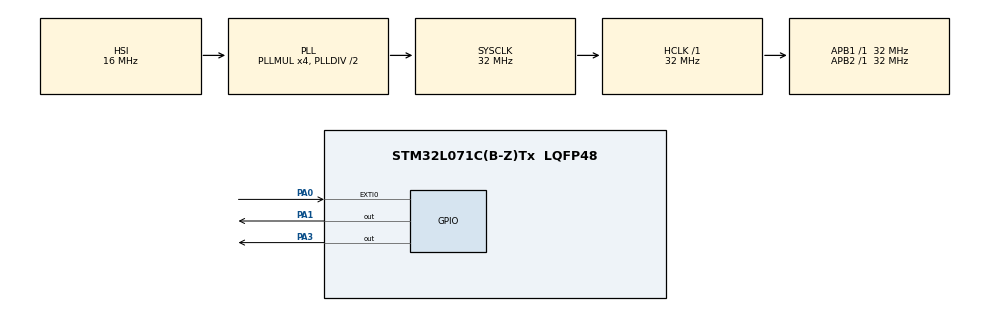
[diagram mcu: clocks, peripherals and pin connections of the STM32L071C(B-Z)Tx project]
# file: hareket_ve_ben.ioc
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Mcu.Family=STM32L0
Mcu.Name=STM32L071C(B-Z)Tx
Mcu.Package=LQFP48
NVIC.EXTI0_1_IRQn=true\:0\:0\:false\:false\:true\:true\:true\:true
PA0.GPIO_ModeDefaultEXTI=GPIO_MODE_IT_RISING
PA0.GPIO_PuPd=GPIO_NOPULL
PA0.Signal=GPXTI0
PA1.Signal=GPIO_Output
PA3.Signal=GPIO_Output
ProjectManager.HeapSize=0x200
ProjectManager.StackSize=0x400
ProjectManager.TargetToolchain=STM32CubeIDE
RCC.AHBFreq_Value=32000000
RCC.APB1Freq_Value=32000000
RCC.APB1TimFreq_Value=32000000
RCC.APB2Freq_Value=32000000
RCC.APB2TimFreq_Value=32000000
RCC.HCLKFreq_Value=32000000
RCC.HSE_VALUE=8000000
RCC.HSI16_VALUE=16000000
RCC.HSI_VALUE=16000000
RCC.LSE_VALUE=32768
RCC.MSI_VALUE=2097000
RCC.PLLMUL=RCC_PLLMUL_4
RCC.SYSCLKFreq_VALUE=32000000
RCC.SYSCLKSource=RCC_SYSCLKSOURCE_PLLCLK
RCC.VCOOutputFreq_Value=64000000
TIM2.Period=0xffff
TIM2.Prescaler=31
VP_TIM2_VS_ClockSourceINT.Mode=Internal
board=custom

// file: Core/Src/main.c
/* USER CODE BEGIN Header */
/**
  ******************************************************************************
  * @file           : main.c
  * @brief          : Main program body
  ******************************************************************************
  * @attention
  *
  * Copyright (c) 2025 STMicroelectronics.
  * All rights reserved.
  *
  * This software is licensed under terms that can be found in the LICENSE file
  * in the root directory of this software component.
  * If no LICENSE file comes with this software, it is provided AS-IS.
  *
  ******************************************************************************
  */
/* USER CODE END Header */
#include "main.h"

/* USER CODE BEGIN Includes */

#include <stdbool.h>
#include "PYD1588.h"
/* USER CODE END Includes */

TIM_HandleTypeDef htim2;

/* USER CODE BEGIN PV */
volatile bool motion_flag = 0;

/* USER CODE END PV */

void SystemClock_Config(void);
static void MX_GPIO_Init(void);
static void MX_TIM2_Init(void);

int main(void)
{

  /* MCU Configuration--------------------------------------------------------*/

  /* Reset of all peripherals, Initializes the Flash interface and the Systick. */
  HAL_Init();

  /* Configure the system clock */
  SystemClock_Config();

  /* Initialize all configured peripherals */
  MX_GPIO_Init();
  MX_TIM2_Init();
  /* USER CODE BEGIN 2 */

  pyd_init(
         100,                        // Threshold
		 PYD_WINDOW_TIME_2S,         // Blind Time
         PYD_PULSE_CNT_2,            // Pulse Counter
         PYD_WINDOW_TIME_4S,         // Window Time
		 PYD_OP_MODE_WAKEUP,      	 // Operation Mode: INT
         PYD_SIGNAL_SRC_BPF,         // Signal Source: BPF
         PYD_HPF_0_4HZ,              // HPF
         PYD_COUNT_WITH_SIGN         // Count mode
     );

  /* USER CODE END 2 */

  /* Infinite loop */
  while (1)
  {

    /* USER CODE BEGIN 3 */

	  if (motion_flag)
	      {
	          HAL_GPIO_WritePin(GPIOA, GPIO_PIN_3, GPIO_PIN_SET);
	          HAL_Delay(2000);
	          HAL_GPIO_WritePin(GPIOA, GPIO_PIN_3, GPIO_PIN_RESET);
	          motion_flag = false;
	      }

  }

  /* USER CODE END 3 */
}

void SystemClock_Config(void)
{
  RCC_OscInitTypeDef RCC_OscInitStruct = {0};
  RCC_ClkInitTypeDef RCC_ClkInitStruct = {0};

  /** Configure the main internal regulator output voltage
  */
  __HAL_PWR_VOLTAGESCALING_CONFIG(PWR_REGULATOR_VOLTAGE_SCALE1);

  /** Initializes the RCC Oscillators according to the specified parameters
  * in the RCC_OscInitTypeDef structure.
  */
  RCC_OscInitStruct.OscillatorType = RCC_OSCILLATORTYPE_HSI;
  RCC_OscInitStruct.HSIState = RCC_HSI_ON;
  RCC_OscInitStruct.HSICalibrationValue = RCC_HSICALIBRATION_DEFAULT;
  RCC_OscInitStruct.PLL.PLLState = RCC_PLL_ON;
  RCC_OscInitStruct.PLL.PLLSource = RCC_PLLSOURCE_HSI;
  RCC_OscInitStruct.PLL.PLLMUL = RCC_PLLMUL_4;
  RCC_OscInitStruct.PLL.PLLDIV = RCC_PLLDIV_2;
  if (HAL_RCC_OscConfig(&RCC_OscInitStruct) != HAL_OK)
  {
    Error_Handler();
  }

  /** Initializes the CPU, AHB and APB buses clocks
  */
  RCC_ClkInitStruct.ClockType = RCC_CLOCKTYPE_HCLK|RCC_CLOCKTYPE_SYSCLK
                              |RCC_CLOCKTYPE_PCLK1|RCC_CLOCKTYPE_PCLK2;
  RCC_ClkInitStruct.SYSCLKSource = RCC_SYSCLKSOURCE_PLLCLK;
  RCC_ClkInitStruct.AHBCLKDivider = RCC_SYSCLK_DIV1;
  RCC_ClkInitStruct.APB1CLKDivider = RCC_HCLK_DIV1;
  RCC_ClkInitStruct.APB2CLKDivider = RCC_HCLK_DIV1;

  if (HAL_RCC_ClockConfig(&RCC_ClkInitStruct, FLASH_LATENCY_1) != HAL_OK)
  {
    Error_Handler();
  }
}

static void MX_TIM2_Init(void)
{

  TIM_ClockConfigTypeDef sClockSourceConfig = {0};
  TIM_MasterConfigTypeDef sMasterConfig = {0};

  htim2.Instance = TIM2;
  htim2.Init.Prescaler = 31;
  htim2.Init.CounterMode = TIM_COUNTERMODE_UP;
  htim2.Init.Period = 0xffff;
  htim2.Init.ClockDivision = TIM_CLOCKDIVISION_DIV1;
  htim2.Init.AutoReloadPreload = TIM_AUTORELOAD_PRELOAD_DISABLE;
  if (HAL_TIM_Base_Init(&htim2) != HAL_OK)
  {
    Error_Handler();
  }
  sClockSourceConfig.ClockSource = TIM_CLOCKSOURCE_INTERNAL;
  if (HAL_TIM_ConfigClockSource(&htim2, &sClockSourceConfig) != HAL_OK)
  {
    Error_Handler();
  }
  sMasterConfig.MasterOutputTrigger = TIM_TRGO_RESET;
  sMasterConfig.MasterSlaveMode = TIM_MASTERSLAVEMODE_DISABLE;
  if (HAL_TIMEx_MasterConfigSynchronization(&htim2, &sMasterConfig) != HAL_OK)
  {
    Error_Handler();
  }

}

static void MX_GPIO_Init(void)
{
  GPIO_InitTypeDef GPIO_InitStruct = {0};

  /* GPIO Ports Clock Enable */
  __HAL_RCC_GPIOA_CLK_ENABLE();

  /*Configure GPIO pin Output Level */
  HAL_GPIO_WritePin(GPIOA, GPIO_PIN_1|GPIO_PIN_3, GPIO_PIN_RESET);

  /*Configure GPIO pin : PA0 */
  GPIO_InitStruct.Pin = GPIO_PIN_0;
  GPIO_InitStruct.Mode = GPIO_MODE_IT_RISING;
  GPIO_InitStruct.Pull = GPIO_NOPULL;
  HAL_GPIO_Init(GPIOA, &GPIO_InitStruct);

  /*Configure GPIO pins : PA1 PA3 */
  GPIO_InitStruct.Pin = GPIO_PIN_1|GPIO_PIN_3;
  GPIO_InitStruct.Mode = GPIO_MODE_OUTPUT_PP;
  GPIO_InitStruct.Pull = GPIO_NOPULL;
  GPIO_InitStruct.Speed = GPIO_SPEED_FREQ_LOW;
  HAL_GPIO_Init(GPIOA, &GPIO_InitStruct);

  /* EXTI interrupt init*/
  HAL_NVIC_SetPriority(EXTI0_1_IRQn, 0, 0);
  HAL_NVIC_EnableIRQ(EXTI0_1_IRQn);

}

/* USER CODE BEGIN 4 */

void delay_us(uint16_t us)
{
    __HAL_TIM_SET_COUNTER(&htim2, 0);
    HAL_TIM_Base_Start(&htim2);
    while (__HAL_TIM_GET_COUNTER(&htim2) < us);
    HAL_TIM_Base_Stop(&htim2);
}
void pyd_clear_interrupt(void)
{
    GPIO_InitTypeDef GPIO_InitStruct = {0};

    // 1. Pin çıkış moduna alınır (OUTPUT) ve LOW yapılır
    GPIO_InitStruct.Pin = PYD_DIRECT_PIN;
    GPIO_InitStruct.Mode = GPIO_MODE_OUTPUT_PP;
    GPIO_InitStruct.Pull = GPIO_NOPULL;
    HAL_GPIO_Init(PYD_DIRECT_PORT, &GPIO_InitStruct);

    HAL_GPIO_WritePin(PYD_DIRECT_PORT, PYD_DIRECT_PIN, GPIO_PIN_RESET);

    // 2. En az 160 mikro saniye bekle
    delay_us(200);

    // 3. Pin tekrar kesme girişi (input interrupt) yapılır
    GPIO_InitStruct.Mode = GPIO_MODE_IT_RISING;
    HAL_GPIO_Init(PYD_DIRECT_PORT, &GPIO_InitStruct);

    pyd_delay_us(650);

}

void HAL_GPIO_EXTI_Callback(uint16_t GPIO_Pin)
{

    if (GPIO_Pin == GPIO_PIN_0)
    {
   motion_flag = true;

   pyd_clear_interrupt();
    }

}

/* USER CODE END 4 */

void Error_Handler(void)
{
  __disable_irq();
  while (1)
  {
  }
}
